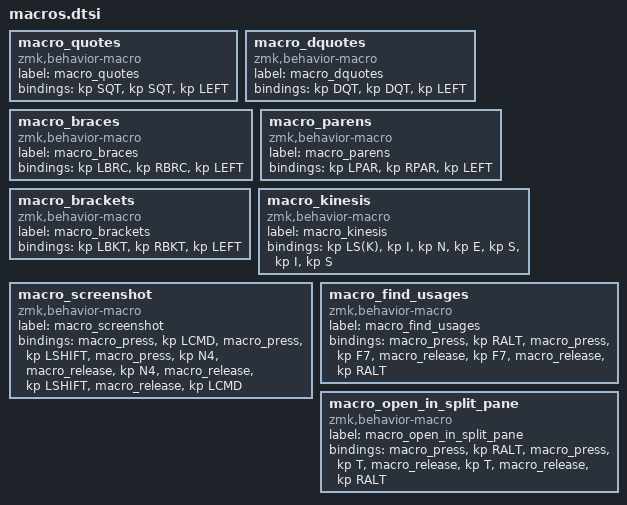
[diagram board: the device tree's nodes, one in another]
macro_quotes: macro_quotes{
compatible = "zmk,behavior-macro";
label = "macro_quotes";
#binding-cells = <0>;
bindings = <&kp SQT>, <&kp SQT>, <&kp LEFT>;
};
macro_dquotes: macro_dquotes{
compatible = "zmk,behavior-macro";
label = "macro_dquotes";
#binding-cells = <0>;
bindings = <&kp DQT>, <&kp DQT>, <&kp LEFT>;
};
macro_braces: macro_braces{
compatible = "zmk,behavior-macro";
label = "macro_braces";
#binding-cells = <0>;
bindings = <&kp LBRC>, <&kp RBRC>, <&kp LEFT>;
};
macro_parens: macro_parens{
compatible = "zmk,behavior-macro";
label = "macro_parens";
#binding-cells = <0>;
bindings = <&kp LPAR>, <&kp RPAR>, <&kp LEFT>;
};
macro_brackets: macro_brackets{
compatible = "zmk,behavior-macro";
label = "macro_brackets";
#binding-cells = <0>;
bindings = <&kp LBKT>, <&kp RBKT>, <&kp LEFT>;
};
macro_kinesis: macro_kinesis{
compatible = "zmk,behavior-macro";
label = "macro_kinesis";
#binding-cells = <0>;
bindings = <&kp LS(K)>, <&kp I>, <&kp N>, <&kp E>, <&kp S>, <&kp I>, <&kp S>;
};
macro_screenshot: macro_screenshot{
compatible = "zmk,behavior-macro";
label = "macro_screenshot";
#binding-cells = <0>;
bindings = <&macro_press &kp LCMD>, <&macro_press &kp LSHIFT>, <&macro_press &kp N4>, <&macro_release &kp N4>, <&macro_release &kp LSHIFT>, <&macro_release &kp LCMD>;
};
macro_find_usages: macro_find_usages{
compatible = "zmk,behavior-macro";
label = "macro_find_usages";
#binding-cells = <0>;
bindings = <&macro_press &kp RALT>, <&macro_press &kp F7>, <&macro_release &kp F7>, <&macro_release &kp RALT>;
};
macro_open_in_split_pane: macro_open_in_split_pane {
  compatible = "zmk,behavior-macro";
  label = "macro_open_in_split_pane";
  #binding-cells = <0>;
  bindings = <&macro_press &kp RALT>, <&macro_press &kp T>, <&macro_release &kp T>, <&macro_release &kp RALT>;
  };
